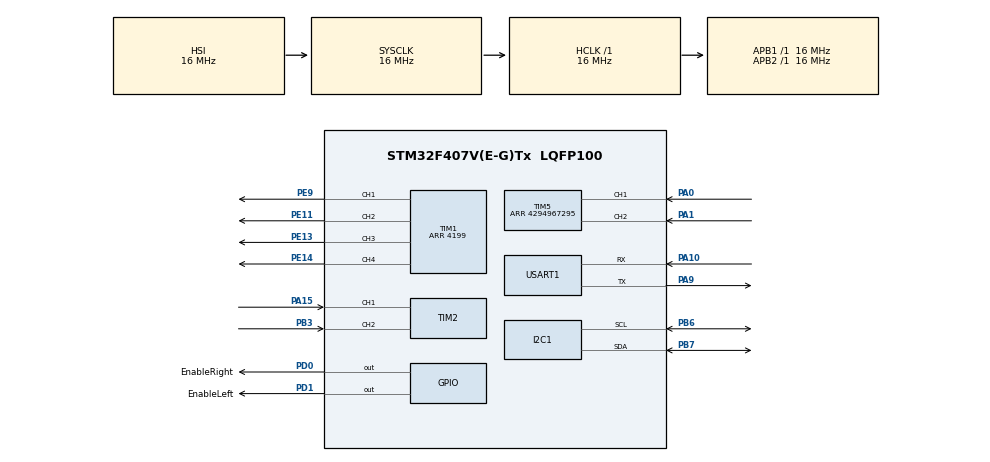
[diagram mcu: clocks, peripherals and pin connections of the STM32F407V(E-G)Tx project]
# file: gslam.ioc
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Dma.Request0=USART1_RX
Dma.Request1=USART1_TX
Dma.USART1_RX.0.Direction=DMA_PERIPH_TO_MEMORY
Dma.USART1_RX.0.FIFOMode=DMA_FIFOMODE_DISABLE
Dma.USART1_RX.0.Instance=DMA2_Stream2
Dma.USART1_RX.0.MemDataAlignment=DMA_MDATAALIGN_BYTE
Dma.USART1_RX.0.MemInc=DMA_MINC_ENABLE
Dma.USART1_RX.0.Mode=DMA_CIRCULAR
Dma.USART1_RX.0.PeriphDataAlignment=DMA_PDATAALIGN_BYTE
Dma.USART1_RX.0.PeriphInc=DMA_PINC_DISABLE
Dma.USART1_RX.0.Priority=DMA_PRIORITY_LOW
Dma.USART1_TX.1.Direction=DMA_MEMORY_TO_PERIPH
Dma.USART1_TX.1.FIFOMode=DMA_FIFOMODE_DISABLE
Dma.USART1_TX.1.Instance=DMA2_Stream7
Dma.USART1_TX.1.MemDataAlignment=DMA_MDATAALIGN_BYTE
Dma.USART1_TX.1.MemInc=DMA_MINC_ENABLE
Dma.USART1_TX.1.Mode=DMA_NORMAL
Dma.USART1_TX.1.PeriphDataAlignment=DMA_PDATAALIGN_BYTE
Dma.USART1_TX.1.PeriphInc=DMA_PINC_DISABLE
Dma.USART1_TX.1.Priority=DMA_PRIORITY_LOW
Mcu.Family=STM32F4
Mcu.Name=STM32F407V(E-G)Tx
Mcu.Package=LQFP100
NVIC.DMA2_Stream2_IRQn=true\:0\:0\:false\:false\:true\:false\:true\:true
NVIC.DMA2_Stream7_IRQn=true\:0\:0\:false\:false\:true\:false\:true\:true
NVIC.PriorityGroup=NVIC_PRIORITYGROUP_4
NVIC.TIM6_DAC_IRQn=true\:0\:0\:false\:false\:true\:true\:true\:true
NVIC.USART1_IRQn=true\:0\:0\:false\:false\:true\:true\:true\:true
PA0-WKUP.Signal=S_TIM5_CH1
PA1.Signal=S_TIM5_CH2
PA10.Mode=Asynchronous
PA10.Signal=USART1_RX
PA13.Mode=Serial_Wire
PA13.Signal=SYS_JTMS-SWDIO
PA14.Mode=Serial_Wire
PA14.Signal=SYS_JTCK-SWCLK
PA15.Signal=S_TIM2_CH1_ETR
PA9.Mode=Asynchronous
PA9.Signal=USART1_TX
PB3.Signal=S_TIM2_CH2
PB6.Mode=I2C
PB6.Signal=I2C1_SCL
PB7.Mode=I2C
PB7.Signal=I2C1_SDA
PD0.GPIO_Label=EnableRight
PD0.Signal=GPIO_Output
PD1.GPIO_Label=EnableLeft
PD1.Signal=GPIO_Output
PE11.Signal=S_TIM1_CH2
PE13.Signal=S_TIM1_CH3
PE14.Signal=S_TIM1_CH4
PE9.Signal=S_TIM1_CH1
ProjectManager.HeapSize=0x200
ProjectManager.StackSize=0x400
ProjectManager.TargetToolchain=STM32CubeIDE
RCC.AHBFreq_Value=16000000
RCC.APB1Freq_Value=16000000
RCC.APB2Freq_Value=16000000
RCC.CortexFreq_Value=16000000
RCC.HSE_VALUE=25000000
RCC.HSI_VALUE=16000000
RCC.LSE_VALUE=32768
RCC.SYSCLKFreq_VALUE=16000000
RCC.VCOOutputFreq_Value=192000000
SH.S_TIM1_CH1.0=TIM1_CH1,PWM Generation1 CH1
SH.S_TIM1_CH2.0=TIM1_CH2,PWM Generation2 CH2
SH.S_TIM1_CH3.0=TIM1_CH3,PWM Generation3 CH3
SH.S_TIM1_CH4.0=TIM1_CH4,PWM Generation4 CH4
SH.S_TIM2_CH1_ETR.0=TIM2_CH1,Encoder_Interface
SH.S_TIM2_CH2.0=TIM2_CH2,Encoder_Interface
SH.S_TIM5_CH1.0=TIM5_CH1,Encoder_Interface
SH.S_TIM5_CH2.0=TIM5_CH2,Encoder_Interface
TIM1.Channel-PWM\ Generation1\ CH1=TIM_CHANNEL_1
TIM1.Channel-PWM\ Generation2\ CH2=TIM_CHANNEL_2
TIM1.Channel-PWM\ Generation3\ CH3=TIM_CHANNEL_3
TIM1.Channel-PWM\ Generation4\ CH4=TIM_CHANNEL_4
TIM1.Period=4199
TIM2.EncoderMode=TIM_ENCODERMODE_TI12
TIM5.EncoderMode=TIM_ENCODERMODE_TI12
TIM5.Period=4294967295
TIM6.Period=8399
TIM6.Prescaler=9
USART1.VirtualMode=VM_ASYNC
VP_TIM1_VS_ClockSourceINT.Mode=Internal
VP_TIM6_VS_ClockSourceINT.Mode=Enable_Timer
board=custom

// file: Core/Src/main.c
/* USER CODE BEGIN Header */
/**
  ******************************************************************************
  * @file           : main.c
  * @brief          : Main program body
  ******************************************************************************
  * @attention
  *
  * Copyright (c) 2026 STMicroelectronics.
  * All rights reserved.
  *
  * This software is licensed under terms that can be found in the LICENSE file
  * in the root directory of this software component.
  * If no LICENSE file comes with this software, it is provided AS-IS.
  *
  ******************************************************************************
  */
/* USER CODE END Header */
#include "main.h"
#include "dma.h"
#include "i2c.h"
#include "tim.h"
#include "usart.h"
#include "gpio.h"

/* USER CODE BEGIN Includes */
#include "app_entry.h"
#include "bsp_uart.h"

/* USER CODE END Includes */

void SystemClock_Config(void);

int main(void)
{

  /* MCU Configuration--------------------------------------------------------*/

  /* Reset of all peripherals, Initializes the Flash interface and the Systick. */
  HAL_Init();

  /* Configure the system clock */
  SystemClock_Config();

  /* Initialize all configured peripherals */
  MX_GPIO_Init();
  MX_DMA_Init();
  MX_TIM1_Init();
  MX_TIM2_Init();
  MX_TIM6_Init();
  MX_TIM5_Init();
  MX_USART1_UART_Init();
  MX_I2C1_Init();
  /* USER CODE BEGIN 2 */
  App_Init();

  /* USER CODE END 2 */

  /* Infinite loop */
  while (1)
  {

    /* USER CODE BEGIN 3 */
    App_RunSlowTick();
  }
  /* USER CODE END 3 */
}

void SystemClock_Config(void)
{
  RCC_OscInitTypeDef RCC_OscInitStruct = {0};
  RCC_ClkInitTypeDef RCC_ClkInitStruct = {0};

  /** Configure the main internal regulator output voltage
  */
  __HAL_RCC_PWR_CLK_ENABLE();
  __HAL_PWR_VOLTAGESCALING_CONFIG(PWR_REGULATOR_VOLTAGE_SCALE1);

  /** Initializes the RCC Oscillators according to the specified parameters
  * in the RCC_OscInitTypeDef structure.
  */
  RCC_OscInitStruct.OscillatorType = RCC_OSCILLATORTYPE_HSI;
  RCC_OscInitStruct.HSIState = RCC_HSI_ON;
  RCC_OscInitStruct.HSICalibrationValue = RCC_HSICALIBRATION_DEFAULT;
  RCC_OscInitStruct.PLL.PLLState = RCC_PLL_NONE;
  if (HAL_RCC_OscConfig(&RCC_OscInitStruct) != HAL_OK)
  {
    Error_Handler();
  }

  /** Initializes the CPU, AHB and APB buses clocks
  */
  RCC_ClkInitStruct.ClockType = RCC_CLOCKTYPE_HCLK|RCC_CLOCKTYPE_SYSCLK
                              |RCC_CLOCKTYPE_PCLK1|RCC_CLOCKTYPE_PCLK2;
  RCC_ClkInitStruct.SYSCLKSource = RCC_SYSCLKSOURCE_HSI;
  RCC_ClkInitStruct.AHBCLKDivider = RCC_SYSCLK_DIV1;
  RCC_ClkInitStruct.APB1CLKDivider = RCC_HCLK_DIV1;
  RCC_ClkInitStruct.APB2CLKDivider = RCC_HCLK_DIV1;

  if (HAL_RCC_ClockConfig(&RCC_ClkInitStruct, FLASH_LATENCY_0) != HAL_OK)
  {
    Error_Handler();
  }
}

/* USER CODE BEGIN 4 */
void HAL_TIM_PeriodElapsedCallback(TIM_HandleTypeDef *htim)
{
  if (htim->Instance == TIM6)
  {
    App_RunFastTick();
  }
}

void HAL_UART_TxCpltCallback(UART_HandleTypeDef *huart)
{
  if (huart->Instance == USART1)
  {
    BspUart_OnTxComplete();
  }
}

/* USER CODE END 4 */

void Error_Handler(void)
{
  __disable_irq();
  while (1)
  {
  }
}
